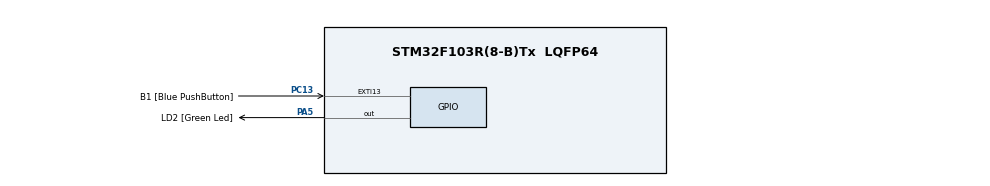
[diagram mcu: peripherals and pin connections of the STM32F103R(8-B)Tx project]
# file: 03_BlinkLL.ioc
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Mcu.Family=STM32F1
Mcu.Name=STM32F103R(8-B)Tx
Mcu.Package=LQFP64
NVIC.EXTI15_10_IRQn=true\:0\:0\:false\:false\:true\:true\:true\:true
NVIC.PriorityGroup=NVIC_PRIORITYGROUP_4
PA13.GPIO_Label=TMS
PA13.Mode=Serial_Wire
PA13.Signal=SYS_JTMS-SWDIO
PA14.GPIO_Label=TCK
PA14.Mode=Serial_Wire
PA14.Signal=SYS_JTCK-SWCLK
PA2.GPIO_Mode=GPIO_MODE_AF_PP
PA2.GPIO_PuPd=GPIO_NOPULL
PA2.GPIO_Speed=GPIO_SPEED_FREQ_LOW
PA2.Signal=USART2_TX
PA3.GPIO_Mode=GPIO_MODE_INPUT
PA3.GPIO_PuPd=GPIO_NOPULL
PA3.GPIO_Speed=GPIO_SPEED_FREQ_LOW
PA3.Signal=USART2_RX
PA5.GPIO_Label=LD2 [Green Led]
PA5.GPIO_ModeDefaultOutputPP=GPIO_MODE_OUTPUT_PP
PA5.GPIO_PuPd=GPIO_NOPULL
PA5.GPIO_Speed=GPIO_SPEED_FREQ_LOW
PA5.Signal=GPIO_Output
PB3.GPIO_Label=SWO
PB3.Signal=SYS_JTDO-TRACESWO
PC13-TAMPER-RTC.GPIO_Label=B1 [Blue PushButton]
PC13-TAMPER-RTC.GPIO_PuPd=GPIO_NOPULL
PC13-TAMPER-RTC.Signal=GPXTI13
PC14-OSC32_IN.Mode=LSE-External-Oscillator
PC14-OSC32_IN.Signal=RCC_OSC32_IN
PC15-OSC32_OUT.Mode=LSE-External-Oscillator
PC15-OSC32_OUT.Signal=RCC_OSC32_OUT
PD0-OSC_IN.Mode=HSE-External-Clock-Source
PD0-OSC_IN.Signal=RCC_OSC_IN
PD1-OSC_OUT.Mode=HSE-External-Clock-Source
PD1-OSC_OUT.Signal=RCC_OSC_OUT
ProjectManager.HeapSize=0x200
ProjectManager.StackSize=0x400
ProjectManager.TargetToolchain=STM32CubeIDE
RCC.AHBFreq_Value=64000000
RCC.APB1CLKDivider=RCC_HCLK_DIV2
RCC.APB1Freq_Value=32000000
RCC.APB1TimFreq_Value=64000000
RCC.APB2Freq_Value=64000000
RCC.APB2TimFreq_Value=64000000
RCC.HCLKFreq_Value=64000000
RCC.PLLMUL=RCC_PLL_MUL8
RCC.PLLSourceVirtual=RCC_PLLSOURCE_HSE
RCC.RTCClockSelection=RCC_RTCCLKSOURCE_LSE
RCC.SYSCLKFreq_VALUE=64000000
RCC.SYSCLKSource=RCC_SYSCLKSOURCE_PLLCLK
RCC.USBFreq_Value=64000000
board=NUCLEO-F103RB

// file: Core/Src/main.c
/* USER CODE BEGIN Header */
/**
  ******************************************************************************
  * @file           : main.c
  * @brief          : Main program body
  ******************************************************************************
  * @attention
  *
  * Copyright (c) 2026 STMicroelectronics.
  * All rights reserved.
  *
  * This software is licensed under terms that can be found in the LICENSE file
  * in the root directory of this software component.
  * If no LICENSE file comes with this software, it is provided AS-IS.
  *
  ******************************************************************************
  */
/**
 * 03_BlinkLL  —  [계층: LL]  CubeMX 생성 코드 + LL(Low-Layer) API 로 LD2(PA5) 점멸
 *
 * 01_BlinkArduino -> 02_BlinkHAL -> 03_BlinkLL -> 04_BlinkReg 시리즈의 세 번째.
 * LL 은 HAL 보다 얇다: 핸들 구조체/상태 머신/타임아웃 없이 레지스터 접근을 인라인 함수로 감싼 정도이다.
 *
 * 하드웨어 대응 (RM0008)
 *   LL_GPIO_TogglePin : GPIOA 의 출력 데이터(ODR 비트 5) 반전
 *   LL_mDelay(1000)   : SysTick_CTRL.COUNTFLAG 를 폴링하며 ms 단위로 대기 (LL_Init1msTick 이 먼저 필요)
 *   LL_APB2_GRP1_EnableClock : RCC_APB2ENR 의 클록 허가 비트
 *   LL_FLASH_SetLatency / LL_RCC_* : FLASH_ACR.LATENCY, RCC_CR/CFGR 로 시스템 클록 설정
 *
 * ISR: SysTick 을 인터럽트로 쓰지 않고 COUNTFLAG 를 폴링하므로 HAL 의 HAL_IncTick 계층이 없다.
 *   콜백(HAL_..._Callback)은 LL 에 존재하지 않는다.
 */
/* USER CODE END Header */
#include "main.h"

void SystemClock_Config(void);
static void MX_GPIO_Init(void);

int main(void)
{

  /* MCU Configuration--------------------------------------------------------*/

  /* Reset of all peripherals, Initializes the Flash interface and the Systick. */
  LL_APB2_GRP1_EnableClock(LL_APB2_GRP1_PERIPH_AFIO);
  LL_APB1_GRP1_EnableClock(LL_APB1_GRP1_PERIPH_PWR);

  /* System interrupt init*/
  NVIC_SetPriorityGrouping(NVIC_PRIORITYGROUP_4);

  /** NOJTAG: JTAG-DP Disabled and SW-DP Enabled
  */
  LL_GPIO_AF_Remap_SWJ_NOJTAG();

  /* Configure the system clock */
  SystemClock_Config();

  /* Initialize all configured peripherals */
  MX_GPIO_Init();

  /* Infinite loop */
  while (1)
  {

    /* USER CODE BEGIN 3 */
    LL_GPIO_TogglePin(LD2_GPIO_Port, LD2_Pin);
    LL_mDelay(1000);
  }
  /* USER CODE END 3 */
}

void SystemClock_Config(void)
{
  LL_FLASH_SetLatency(LL_FLASH_LATENCY_2);
  while(LL_FLASH_GetLatency()!= LL_FLASH_LATENCY_2)
  {
  }
  LL_RCC_HSE_EnableBypass();
  LL_RCC_HSE_Enable();

   /* Wait till HSE is ready */
  while(LL_RCC_HSE_IsReady() != 1)
  {

  }
  LL_RCC_PLL_ConfigDomain_SYS(LL_RCC_PLLSOURCE_HSE_DIV_1, LL_RCC_PLL_MUL_8);
  LL_RCC_PLL_Enable();

   /* Wait till PLL is ready */
  while(LL_RCC_PLL_IsReady() != 1)
  {

  }
  LL_RCC_SetAHBPrescaler(LL_RCC_SYSCLK_DIV_1);
  LL_RCC_SetAPB1Prescaler(LL_RCC_APB1_DIV_2);
  LL_RCC_SetAPB2Prescaler(LL_RCC_APB2_DIV_1);
  LL_RCC_SetSysClkSource(LL_RCC_SYS_CLKSOURCE_PLL);

   /* Wait till System clock is ready */
  while(LL_RCC_GetSysClkSource() != LL_RCC_SYS_CLKSOURCE_STATUS_PLL)
  {

  }
  LL_Init1msTick(64000000);
  LL_SetSystemCoreClock(64000000);
}

static void MX_GPIO_Init(void)
{
  LL_EXTI_InitTypeDef EXTI_InitStruct = {0};
  LL_GPIO_InitTypeDef GPIO_InitStruct = {0};

  /* GPIO Ports Clock Enable */
  LL_APB2_GRP1_EnableClock(LL_APB2_GRP1_PERIPH_GPIOC);
  LL_APB2_GRP1_EnableClock(LL_APB2_GRP1_PERIPH_GPIOD);
  LL_APB2_GRP1_EnableClock(LL_APB2_GRP1_PERIPH_GPIOA);
  LL_APB2_GRP1_EnableClock(LL_APB2_GRP1_PERIPH_GPIOB);

  /**/
  LL_GPIO_ResetOutputPin(LD2_GPIO_Port, LD2_Pin);

  /**/
  LL_GPIO_AF_SetEXTISource(LL_GPIO_AF_EXTI_PORTC, LL_GPIO_AF_EXTI_LINE13);

  /**/
  EXTI_InitStruct.Line_0_31 = LL_EXTI_LINE_13;
  EXTI_InitStruct.LineCommand = ENABLE;
  EXTI_InitStruct.Mode = LL_EXTI_MODE_IT;
  EXTI_InitStruct.Trigger = LL_EXTI_TRIGGER_RISING;
  LL_EXTI_Init(&EXTI_InitStruct);

  /**/
  LL_GPIO_SetPinMode(B1_GPIO_Port, B1_Pin, LL_GPIO_MODE_FLOATING);

  /**/
  GPIO_InitStruct.Pin = LL_GPIO_PIN_2;
  GPIO_InitStruct.Mode = LL_GPIO_MODE_ALTERNATE;
  GPIO_InitStruct.Speed = LL_GPIO_SPEED_FREQ_LOW;
  GPIO_InitStruct.OutputType = LL_GPIO_OUTPUT_PUSHPULL;
  LL_GPIO_Init(GPIOA, &GPIO_InitStruct);

  /**/
  GPIO_InitStruct.Pin = LL_GPIO_PIN_3;
  GPIO_InitStruct.Mode = LL_GPIO_MODE_FLOATING;
  LL_GPIO_Init(GPIOA, &GPIO_InitStruct);

  /**/
  GPIO_InitStruct.Pin = LD2_Pin;
  GPIO_InitStruct.Mode = LL_GPIO_MODE_OUTPUT;
  GPIO_InitStruct.Speed = LL_GPIO_SPEED_FREQ_LOW;
  GPIO_InitStruct.OutputType = LL_GPIO_OUTPUT_PUSHPULL;
  LL_GPIO_Init(LD2_GPIO_Port, &GPIO_InitStruct);

  /* EXTI interrupt init*/
  NVIC_SetPriority(EXTI15_10_IRQn, NVIC_EncodePriority(NVIC_GetPriorityGrouping(),0, 0));
  NVIC_EnableIRQ(EXTI15_10_IRQn);

}

void Error_Handler(void)
{
  __disable_irq();
  while (1)
  {
  }
}
